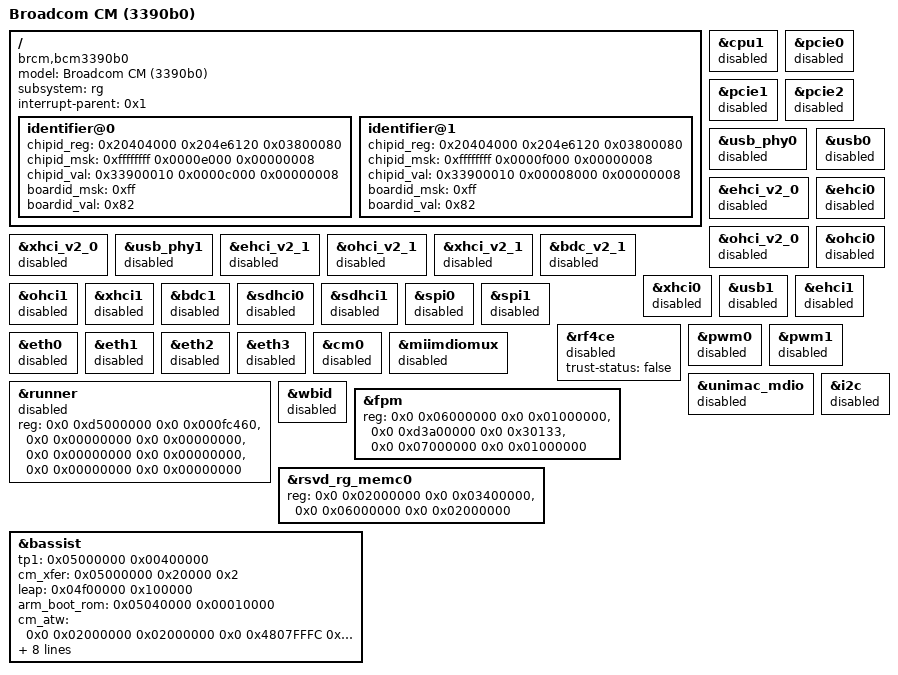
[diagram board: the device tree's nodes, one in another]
/dts-v1/;

/ {
	model = "Broadcom CM (3390b0)";
	compatible = "brcm,bcm3390b0", "brcm,brcmstb";
	subsystem = "rg";
	#address-cells = <0x2>;
	#size-cells = <0x2>;
	interrupt-parent = <0x1>;

	identifier@0 {
			    /*			     BMU mbox0: */
			    /* chip id    mfg id     on battery */
		chipid_reg = < 0x20404000 0x204e6120 0x03800080 >;
		chipid_msk = < 0xffffffff 0x0000e000 0x00000008 >;
		chipid_val = < 0x33900010 0x0000c000 0x00000008 >;
			     /*
			      * Only boards supporting battery. Can't rely on
			      * BMU's mbox0 power state on non-battery boards.
			      */
			     /* VCMS */
		boardid_msk = < 0xff >;
		boardid_val = < 0x82 >;
	};

	identifier@1 {
			    /*			     BMU mbox0: */
			    /* chip id    mfg id     on battery */
		chipid_reg = < 0x20404000 0x204e6120 0x03800080 >;
		chipid_msk = < 0xffffffff 0x0000f000 0x00000008 >;
		chipid_val = < 0x33900010 0x00008000 0x00000008 >;
			     /*
			      * Only boards supporting battery. Can't rely on
			      * BMU's mbox0 power state on non-battery boards.
			      */
			     /* VCMS */
		boardid_msk = < 0xff >;
		boardid_val = < 0x82 >;
	};
};

/include/ "rg.3390b0-bolt.dtsi"
/include/ "rg.3390-base.dtsi"

/********************************************************************
 * any nodes that appear below are platform specific additions and
 * replacements.
 * The dtc will add or replace any properties in the nodes
 * below to the same nodes that appear in include files above.
 * If the property does not exist in the node above it will be added.
 * If the property does exist it will replace it.
 ********************************************************************/
&cpu1 {
	status = "disabled";
};

&pcie0 {
	status = "disabled";
};

&pcie1 {
	status = "disabled";
};

&pcie2 {
	status = "disabled";
};

&usb_phy0 {
	status = "disabled";
};

&ehci_v2_0 {
	status = "disabled";
};

&ohci_v2_0 {
	status = "disabled";
};

&xhci_v2_0 {
	status = "disabled";
};

&usb_phy1 {
	status = "disabled";
};

&ehci_v2_1 {
	status = "disabled";
};

&ohci_v2_1 {
	status = "disabled";
};

&xhci_v2_1 {
	status = "disabled";
};

&bdc_v2_1 {
	status = "disabled";
};

&usb0 {
	status = "disabled";
};

&ehci0 {
	status = "disabled";
};

&ohci0 {
	status = "disabled";
};

&xhci0 {
	status = "disabled";
};

&usb1 {
	status = "disabled";
};

&ehci1 {
	status = "disabled";
};

&ohci1 {
	status = "disabled";
};

&xhci1 {
	status = "disabled";
};

&bdc1 {
	status = "disabled";
};

&sdhci0 {
	status = "disabled";
};

&sdhci1 {
	status = "disabled";
};

&spi0 {
	status = "disabled";
};

&spi1 {
	status = "disabled";
};

&rf4ce {
	status = "disabled";
	/* Old BOLT versions will set the above status to "ok" for all platforms,
	so add another property for new software images to discern whether
	status property is to be obeyed. Only valid platforms have this new property
	set correctly to "true". */
	trust-status = "false";
};

&pwm0 {
	status = "disabled";
};

&pwm1 {
	status = "disabled";
};

&eth0 {
	status = "disabled";
};

&eth1 {
	status = "disabled";
};

&eth2 {
	status = "disabled";
};

&eth3 {
	status = "disabled";
};

&cm0 {
	status = "disabled";
};

&miimdiomux {
	status = "disabled";
};

&unimac_mdio {
	status = "disabled";
};

&runner {
	status = "disabled";
};

&i2c {
	status = "disabled";
};

&wbid {
	status = "disabled";
};

&fpm {
	reg = <0x0 0x06000000 0x0 0x01000000>,	/* Free Pool 0	*/
	      <0x0 0xd3a00000 0x0 0x30133>,	/* Registers	*/
	      <0x0 0x07000000 0x0 0x01000000>;	/* Free Pool 1	*/
};

&runner {
	reg = <0x0 0xd5000000 0x0 0x000fc460>,	/* Registers			*/
	      <0x0 0x00000000 0x0 0x00000000>,	/* Runner Extra Memory 0	*/
	      <0x0 0x00000000 0x0 0x00000000>,	/* Runner Extra Memory 1	*/
	      <0x0 0x00000000 0x0 0x00000000>;	/* Runner NAT Cache		*/
};

&rsvd_rg_memc0 {
	reg = <0x0 0x02000000 0x0 0x03400000>, /* CM + leap */
	      <0x0 0x06000000 0x0 0x02000000>; /* FPM + cm extra */
};

&bassist {
	    tp1 = < 0x05000000 0x00400000 >; //start, size
	    cm_xfer = < 0x05000000 0x20000 0x2 >; //start, size, count
	    leap = < 0x04f00000 0x100000>; //start, size
	    arm_boot_rom = <0x05040000 0x00010000>; //start, size
	    cm_atw = < 0x0 0x02000000 0x02000000 0x0 0x4807FFFC 0x0 0x0 0x0 >; //index, start, size, destination, client0-3
	    cm_atw_extra = < 0x3 0x04000000 0x01000000 0x02000000 0x4807FFFC 0x0 0x0 0x0 >; //index, start, size, destination, client0-3
	    cm_dsp_atw = < 0x1 0x05000000 0x00400000 0x07c00000 0x4804FFFC 0x0 0x0 0x0 >; //index, start, size, destination, client0-3
	    cm_boot_atw = < 0x2 0x05050000 0x10000 0x1fc00000 0x40000 0x0 0x0 0x0 >; //index, start, size, destination, client0-3
	    cm_boot_atw_extra = < 0x4 0x04e00000 0x00200000 0x03e00000 0x40000 0x0 0x0 0x0 >; //index, start, size, destination, client0-3
};
